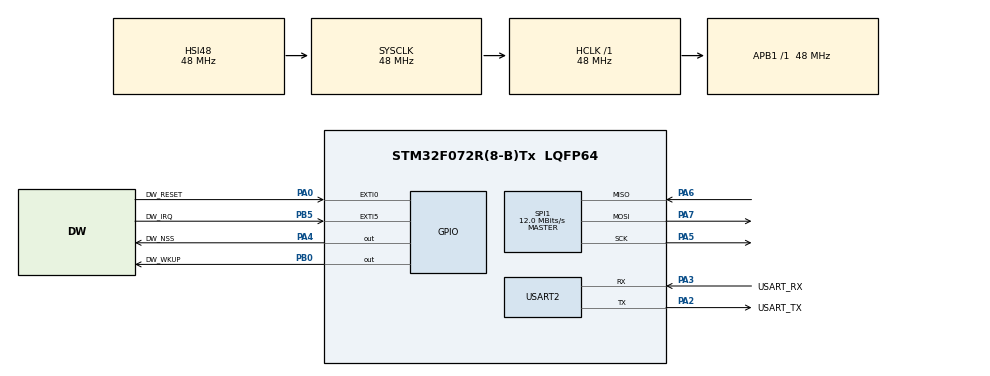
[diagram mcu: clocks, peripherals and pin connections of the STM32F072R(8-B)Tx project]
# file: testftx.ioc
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Mcu.Family=STM32F0
Mcu.Name=STM32F072R(8-B)Tx
Mcu.Package=LQFP64
NVIC.EXTI0_1_IRQn=true\:0\:0\:false\:false\:true\:true\:true\:true
NVIC.EXTI4_15_IRQn=true\:0\:0\:false\:false\:true\:true\:true\:true
PA0.GPIO_Label=DW_RESET
PA0.Signal=GPXTI0
PA13.GPIO_Label=TMS
PA13.Mode=Serial_Wire
PA13.Signal=SYS_SWDIO
PA14.GPIO_Label=TCK
PA14.Mode=Serial_Wire
PA14.Signal=SYS_SWCLK
PA2.GPIO_Label=USART_TX
PA2.GPIO_Mode=GPIO_MODE_AF_PP
PA2.GPIO_PuPd=GPIO_NOPULL
PA2.GPIO_Speed=GPIO_SPEED_FREQ_LOW
PA2.Mode=Asynchronous
PA2.Signal=USART2_TX
PA3.GPIO_Label=USART_RX
PA3.GPIO_Mode=GPIO_MODE_AF_PP
PA3.GPIO_PuPd=GPIO_NOPULL
PA3.GPIO_Speed=GPIO_SPEED_FREQ_LOW
PA3.Mode=Asynchronous
PA3.Signal=USART2_RX
PA4.GPIO_Label=DW_NSS
PA4.PinState=GPIO_PIN_SET
PA4.Signal=GPIO_Output
PA5.Mode=Full_Duplex_Master
PA5.Signal=SPI1_SCK
PA6.Mode=Full_Duplex_Master
PA6.Signal=SPI1_MISO
PA7.Mode=Full_Duplex_Master
PA7.Signal=SPI1_MOSI
PB0.GPIO_Label=DW_WKUP
PB0.GPIO_ModeDefaultOutputPP=GPIO_MODE_OUTPUT_OD
PB0.GPIO_PuPd=GPIO_NOPULL
PB0.PinState=GPIO_PIN_SET
PB0.Signal=GPIO_Output
PB5.GPIO_Label=DW_IRQ
PB5.Signal=GPXTI5
PC14-OSC32_IN.Mode=LSE-External-Oscillator
PC14-OSC32_IN.Signal=RCC_OSC32_IN
PC15-OSC32_OUT.Mode=LSE-External-Oscillator
PC15-OSC32_OUT.Signal=RCC_OSC32_OUT
PF0-OSC_IN.Mode=HSE-External-Clock-Source
PF0-OSC_IN.Signal=RCC_OSC_IN
PF1-OSC_OUT.Signal=RCC_OSC_OUT
ProjectManager.HeapSize=0x200
ProjectManager.StackSize=0x400
ProjectManager.TargetToolchain=STM32CubeIDE
RCC.AHBFreq_Value=48000000
RCC.APB1Freq_Value=48000000
RCC.APB1TimFreq_Value=48000000
RCC.FLatency-AdvancedSettings=FLASH_LATENCY_1
RCC.HCLKFreq_Value=48000000
RCC.PLLDivider=RCC_PREDIV_DIV2
RCC.PLLMUL=RCC_PLL_MUL12
RCC.PREFETCH_ENABLE-AdvancedSettings=1
RCC.SYSCLKFreq_VALUE=48000000
RCC.SYSCLKSource=RCC_SYSCLKSOURCE_HSI48
SPI1.BaudRatePrescaler=SPI_BAUDRATEPRESCALER_4
SPI1.CalculateBaudRate=12.0 MBits/s
SPI1.DataSize=SPI_DATASIZE_8BIT
SPI1.Direction=SPI_DIRECTION_2LINES
SPI1.Mode=SPI_MODE_MASTER
SPI1.VirtualType=VM_MASTER
USART2.VirtualMode=VM_ASYNC
USART2.VirtualMode-Asynchronous=VM_ASYNC
board=NUCLEO-F072RB

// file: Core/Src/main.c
/* USER CODE BEGIN Header */
/**
  ******************************************************************************
  * @file           : main.c
  * @brief          : Main program body
  ******************************************************************************
  * @attention
  *
  * Copyright (c) 2026 STMicroelectronics.
  * All rights reserved.
  *
  * This software is licensed under terms that can be found in the LICENSE file
  * in the root directory of this software component.
  * If no LICENSE file comes with this software, it is provided AS-IS.
  *
  ******************************************************************************
  */
/* USER CODE END Header */
#include "main.h"
#include "spi.h"
#include "usart.h"
#include "gpio.h"
#include "port.h"

void SystemClock_Config(void);

/* USER CODE BEGIN 0 */
extern int dw_main(void);
/* USER CODE END 0 */

int main(void)
{

  /* MCU Configuration--------------------------------------------------------*/

  /* Reset of all peripherals, Initializes the Flash interface and the Systick. */
  HAL_Init();

  /* Configure the system clock */
  SystemClock_Config();

  /* Initialize all configured peripherals */
  MX_GPIO_Init();
  MX_USART2_UART_Init();
  MX_SPI1_Init();
  /* USER CODE BEGIN 2 */

   setup_DW1000RSTnIRQ(0);
   dw_main();
  /* USER CODE END 2 */

  /* Infinite loop */
  while (1)
  {

  }
}

void SystemClock_Config(void)
{
  RCC_OscInitTypeDef RCC_OscInitStruct = {0};
  RCC_ClkInitTypeDef RCC_ClkInitStruct = {0};
  RCC_PeriphCLKInitTypeDef PeriphClkInit = {0};

  /** Initializes the RCC Oscillators according to the specified parameters
  * in the RCC_OscInitTypeDef structure.
  */
  RCC_OscInitStruct.OscillatorType = RCC_OSCILLATORTYPE_HSI48;
  RCC_OscInitStruct.HSI48State = RCC_HSI48_ON;
  RCC_OscInitStruct.PLL.PLLState = RCC_PLL_NONE;
  if (HAL_RCC_OscConfig(&RCC_OscInitStruct) != HAL_OK)
  {
    Error_Handler();
  }

  /** Initializes the CPU, AHB and APB buses clocks
  */
  RCC_ClkInitStruct.ClockType = RCC_CLOCKTYPE_HCLK|RCC_CLOCKTYPE_SYSCLK
                              |RCC_CLOCKTYPE_PCLK1;
  RCC_ClkInitStruct.SYSCLKSource = RCC_SYSCLKSOURCE_HSI48;
  RCC_ClkInitStruct.AHBCLKDivider = RCC_SYSCLK_DIV1;
  RCC_ClkInitStruct.APB1CLKDivider = RCC_HCLK_DIV1;

  if (HAL_RCC_ClockConfig(&RCC_ClkInitStruct, FLASH_LATENCY_1) != HAL_OK)
  {
    Error_Handler();
  }
  PeriphClkInit.PeriphClockSelection = RCC_PERIPHCLK_USART2;
  PeriphClkInit.Usart2ClockSelection = RCC_USART2CLKSOURCE_PCLK1;
  if (HAL_RCCEx_PeriphCLKConfig(&PeriphClkInit) != HAL_OK)
  {
    Error_Handler();
  }
}

void Error_Handler(void)
{
  __disable_irq();
  while (1)
  {
  }
}
